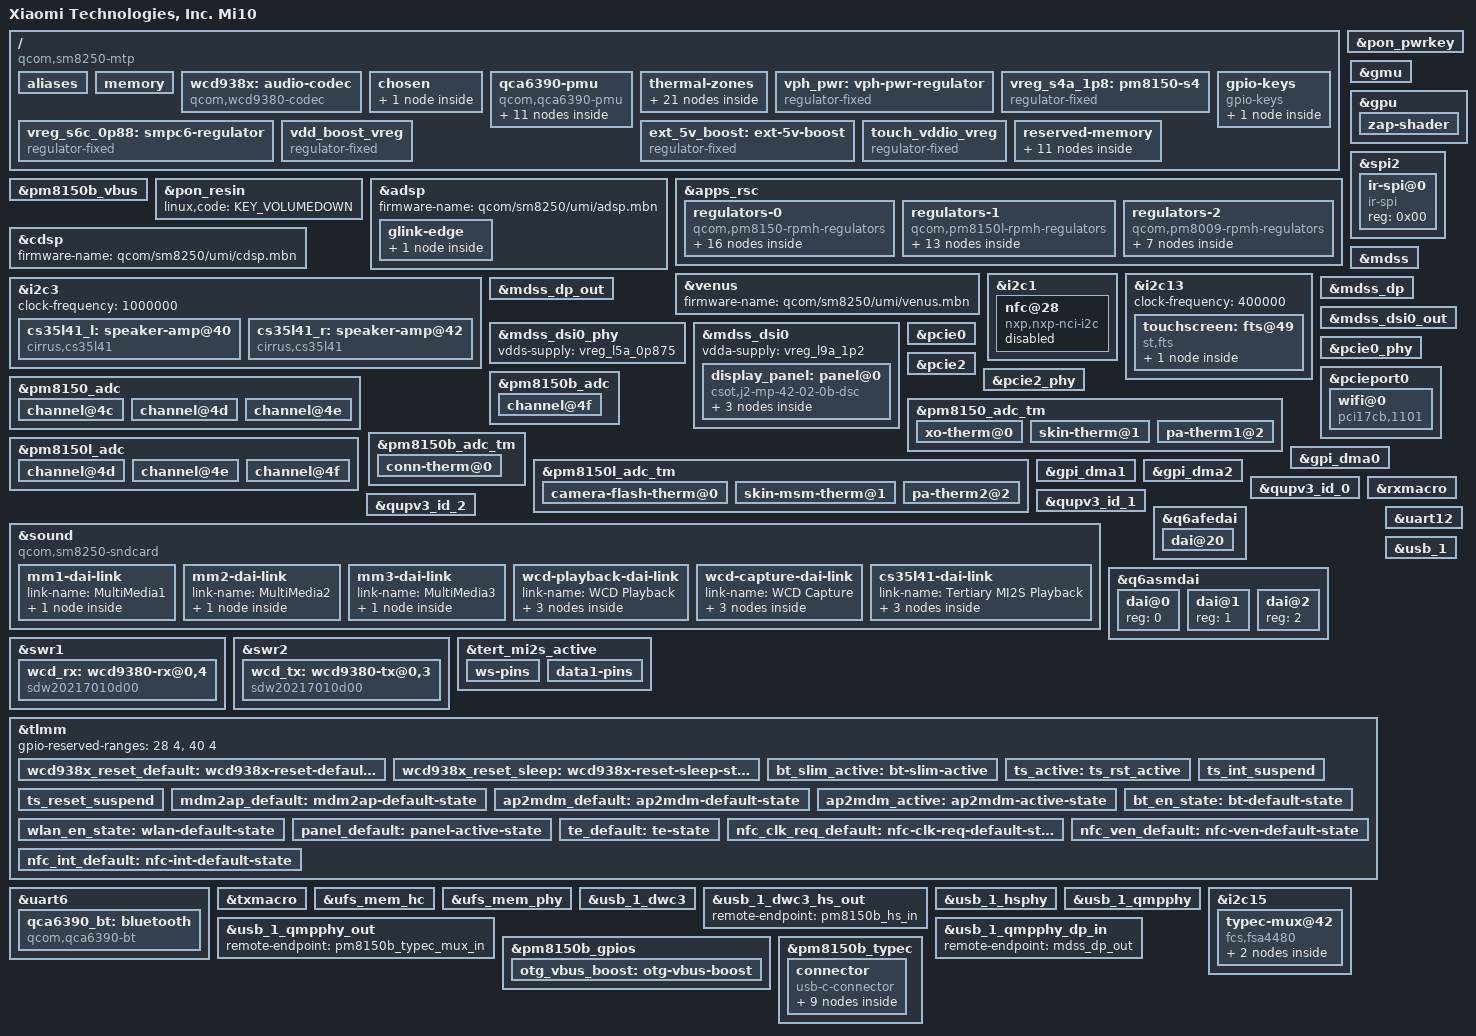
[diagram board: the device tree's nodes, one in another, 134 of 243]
// SPDX-License-Identifier: BSD-3-Clause
/*
 * Copyright (c) 2020, The Linux Foundation. All rights reserved.
 */

/dts-v1/;

#include <dt-bindings/regulator/qcom,rpmh-regulator.h>
#include <dt-bindings/sound/qcom,q6afe.h>
#include <dt-bindings/sound/qcom,q6asm.h>
#include <dt-bindings/gpio/gpio.h>
#include <dt-bindings/usb/pd.h>
#include "sm8250.dtsi"
#include "pm8150.dtsi"
#include "pm8150b.dtsi"
#include "pm8150l.dtsi"
#include "pm8009.dtsi"

/delete-node/ &adsp_mem;
/delete-node/ &cdsp_secure_heap;
/delete-node/ &slpi_mem;
/delete-node/ &spss_mem;
/delete-node/ &xbl_aop_mem;

/ {
	model = "Xiaomi Technologies, Inc. Mi10";
	compatible = "qcom,sm8250-mtp", "qcom,sm8250";
	chassis-type = "handset";
	qcom,msm-id = <0x164 0x20001>;
	qcom,board-id = <0x2b 0x00>;

	aliases {
		serial0 = &uart12;
		serial1 = &uart6;
	};
	
	memory {
		ddr_device_type = <0x08>;
		device_type = "memory";
		#address-cells = <2>;
		#size-cells = <2>;
		reg = 	<0x0 0x80000000 0x0 0x3b800000>,
				<0x1 0x80000000 0x1 0x0>,
				<0x0 0xc0000000 0x0 0xc0000000>;
	};

	wcd938x: audio-codec {
		compatible = "qcom,wcd9380-codec";
		status = "okay";
		reset-gpios = <&tlmm 32 GPIO_ACTIVE_LOW>;

		vdd-buck-supply = <&vreg_s4a_1p8>;
		vdd-rxtx-supply = <&vreg_s4a_1p8>;
		vdd-io-supply = <&vreg_s4a_1p8>;
		vdd-mic-bias-supply = <&vreg_bob>;

		qcom,micbias1-microvolt = <1800000>;
		qcom,micbias2-microvolt = <1800000>;
		qcom,micbias3-microvolt = <1800000>;
		qcom,micbias4-microvolt = <1800000>;
		qcom,mbhc-buttons-vthreshold-microvolt = <75000 150000 237000 500000 500000 500000 500000 500000>;
		qcom,mbhc-headset-vthreshold-microvolt = <1700000>;
		qcom,mbhc-headphone-vthreshold-microvolt = <50000>;
		qcom,rx-device = <&wcd_rx>;
		qcom,tx-device = <&wcd_tx>;

		#sound-dai-cells = <1>;
	};

	// battery: battery {
	// 	compatible = "simple-battery";
	// 	voltage-min-design-microvolt = <3400000>;
	// 	voltage-max-design-microvolt = <4400000>;
	// 	charge-full-design-microamp-hours = <4680000>;
	// 	energy-full-design-microwatt-hours = <18400000>;
	// };

	chosen {
		#address-cells = <2>;
		#size-cells = <2>;
		ranges;
		// stdout-path = "serial0:115200n8";
		// stdout-path = "display0";
		bootargs = "panic=30 loglevel=7 console=ttyS0,115200 console=tty1 rootfs_part=sda36 root=/dev/sda36 rw rootwait systemd.journald.forward_to_console=true systemd.log_level=debug systemd.log_target=kmsg log_buf_len=10M printk.devkmsg=on";
		//  pd_ignore_unused clk_ignore_unused 
		display0: framebuffer@9c000000 {
			compatible = "simple-framebuffer";
			reg = <0x0 0x9c000000 0x0 0x2300000>;
			width = <1080>;
			height = <2340>;
			stride = <(1080 * 4)>;
			format = "a8r8g8b8";
			status = "disabled";
			/*
			 * That's a lot of clocks, but it's necessary due
			 * to unused clk cleanup & no panel driver yet..
			 */
			// clocks = <&dispcc DISP_CC_MDSS_AHB_CLK>,
			// 	 <&gcc GCC_DISP_HF_AXI_CLK>,
			// 	 <&gcc GCC_DISP_SF_AXI_CLK>,
			// 	 <&dispcc DISP_CC_MDSS_VSYNC_CLK>,
			// 	 <&dispcc DISP_CC_MDSS_MDP_CLK>,
			// 	 <&dispcc DISP_CC_MDSS_BYTE0_CLK>,
			// 	 <&dispcc DISP_CC_MDSS_BYTE0_INTF_CLK>,
			// 	 <&dispcc DISP_CC_MDSS_PCLK0_CLK>,
			// 	 <&dispcc DISP_CC_MDSS_ESC0_CLK>;
			// power-domains = <&dispcc MDSS_GDSC>;
		};
	};

	qca6390-pmu {
		compatible = "qcom,qca6390-pmu";

		pinctrl-names = "default";
		pinctrl-0 = <&bt_en_state>, <&wlan_en_state>;

		vddaon-supply = <&vreg_s6a_0p95>;
		vddpmu-supply = <&vreg_s2f_0p95>;
		vddrfa0p95-supply = <&vreg_s2f_0p95>;
		vddrfa1p3-supply = <&vreg_s8c_1p3>;
		vddrfa1p9-supply = <&vreg_s5a_1p9>;
		vddpcie1p3-supply = <&vreg_s8c_1p3>;
		vddpcie1p9-supply = <&vreg_s5a_1p9>;
		vddio-supply = <&vreg_s4a_1p8>;

		wlan-enable-gpios = <&tlmm 20 GPIO_ACTIVE_HIGH>;
		bt-enable-gpios = <&tlmm 21 GPIO_ACTIVE_HIGH>;

		regulators {
			vreg_pmu_rfa_cmn: ldo0 {
				regulator-name = "vreg_pmu_rfa_cmn";
			};

			vreg_pmu_aon_0p59: ldo1 {
				regulator-name = "vreg_pmu_aon_0p59";
			};

			vreg_pmu_wlcx_0p8: ldo2 {
				regulator-name = "vreg_pmu_wlcx_0p8";
			};

			vreg_pmu_wlmx_0p85: ldo3 {
				regulator-name = "vreg_pmu_wlmx_0p85";
			};

			vreg_pmu_btcmx_0p85: ldo4 {
				regulator-name = "vreg_pmu_btcmx_0p85";
			};

			vreg_pmu_rfa_0p8: ldo5 {
				regulator-name = "vreg_pmu_rfa_0p8";
			};

			vreg_pmu_rfa_1p2: ldo6 {
				regulator-name = "vreg_pmu_rfa_1p2";
			};

			vreg_pmu_rfa_1p7: ldo7 {
				regulator-name = "vreg_pmu_rfa_1p7";
			};

			vreg_pmu_pcie_0p9: ldo8 {
				regulator-name = "vreg_pmu_pcie_0p9";
			};

			vreg_pmu_pcie_1p8: ldo9 {
				regulator-name = "vreg_pmu_pcie_1p8";
			};
		};
	};

	thermal-zones {
		camera-thermal {
			polling-delay-passive = <0>;
			polling-delay = <0>;
			thermal-sensors = <&pm8150l_adc_tm 0>;

			trips {
				active-config0 {
					temperature = <125000>;
					hysteresis = <1000>;
					type = "passive";
				};
			};
		};

		conn-thermal {
			polling-delay-passive = <0>;
			polling-delay = <0>;
			thermal-sensors = <&pm8150b_adc_tm 0>;

			trips {
				active-config0 {
					temperature = <125000>;
					hysteresis = <1000>;
					type = "passive";
				};
			};
		};

		mmw-pa1-thermal {
			polling-delay-passive = <0>;
			polling-delay = <0>;
			thermal-sensors = <&pm8150_adc_tm 2>;

			trips {
				active-config0 {
					temperature = <125000>;
					hysteresis = <1000>;
					type = "passive";
				};
			};
		};

		mmw-pa2-thermal {
			polling-delay-passive = <0>;
			polling-delay = <0>;
			thermal-sensors = <&pm8150l_adc_tm 2>;

			trips {
				active-config0 {
					temperature = <125000>;
					hysteresis = <1000>;
					type = "passive";
				};
			};
		};

		skin-msm-thermal {
			polling-delay-passive = <0>;
			polling-delay = <0>;
			thermal-sensors = <&pm8150l_adc_tm 1>;

			trips {
				active-config0 {
					temperature = <125000>;
					hysteresis = <1000>;
					type = "passive";
				};
			};
		};

		skin-thermal {
			polling-delay-passive = <0>;
			polling-delay = <0>;
			thermal-sensors = <&pm8150_adc_tm 1>;

			trips {
				active-config0 {
					temperature = <125000>;
					hysteresis = <1000>;
					type = "passive";
				};
			};
		};

		xo-thermal {
			polling-delay-passive = <0>;
			polling-delay = <0>;
			thermal-sensors = <&pm8150_adc_tm 0>;

			trips {
				active-config0 {
					temperature = <125000>;
					hysteresis = <1000>;
					type = "passive";
				};
			};
		};
	};

	// slimbam: dma-controller@3a84000 {
	// 	compatible = "qcom,bam-v1.7.4", "qcom,bam-v1.7.0";
	// 	reg = <0x0 0x3a84000 0x0 0x2c000>;
	// 	interrupts = <GIC_SPI 164 IRQ_TYPE_LEVEL_HIGH>;
	// 	#dma-cells = <1>;
	// 	qcom,ee = <1>;
	// 	qcom,num-ees = <2>;
	// 	num-channels = <31>;
	// 	qcom,controlled-remotely;
	// 	iommus = <&apps_smmu 0x1826 0x00>;
	// };

	// slim_msm: slim-ngd@3ac0000  {
	// 	compatible = "qcom,slim-ngd-v1.5.0";
	// 	reg = <0 0x3ac0000 0 0x2c000>;
	// 	interrupts = <GIC_SPI 163 IRQ_TYPE_LEVEL_HIGH>;
	// 	dmas = <&slimbam 3>, <&slimbam 4>;
	// 	dma-names = "rx", "tx";
	// 	#address-cells = <1>;
	// 	#size-cells = <0>;
	// 	iommus = <&apps_smmu 0x1830 0x01>,
	// 			<&apps_smmu 0x182f 0x00>;
	// 	status = "disabled";
	// };

	vph_pwr: vph-pwr-regulator {
		compatible = "regulator-fixed";
		regulator-name = "vph_pwr";
		regulator-min-microvolt = <3700000>;
		regulator-max-microvolt = <3700000>;
	};

	vreg_s4a_1p8: pm8150-s4 {
		compatible = "regulator-fixed";
		regulator-name = "vreg_s4a_1p8";

		regulator-min-microvolt = <1800000>;
		regulator-max-microvolt = <1800000>;

		regulator-always-on;
		regulator-boot-on;

		vin-supply = <&vph_pwr>;
	};

	vreg_s6c_0p88: smpc6-regulator {
		compatible = "regulator-fixed";
		regulator-name = "vreg_s6c_0p88";

		regulator-min-microvolt = <880000>;
		regulator-max-microvolt = <880000>;
		regulator-always-on;
		vin-supply = <&vph_pwr>;
	};

	gpio-keys {
		compatible = "gpio-keys";
		key-vol-up {
			label = "Volume Up";
			linux,code = <KEY_VOLUMEUP>;
			gpios = <&pm8150_gpios 6 GPIO_ACTIVE_LOW>;
		};
	};

	vdd_boost_vreg: vdd_boost_vreg {
		compatible = "regulator-fixed";
		regulator-name = "vdd_boost_vreg";
		regulator-min-microvolt = <5000000>;
		regulator-max-microvolt = <5000000>;
		startup-delay-us = <4000>;
		enable-active-high;
		regulator-always-on;
		gpio = <&pm8150b_gpios 5 0>;
	 };

	ext_5v_boost: ext-5v-boost {
		status = "okay";
		compatible = "regulator-fixed";
		gpio = <&pm8150b_gpios 12 GPIO_ACTIVE_HIGH>;
		pinctrl-names = "default";
		pinctrl-0 = <&otg_vbus_boost>;
		regulator-min-microvolt = <5000000>;
		regulator-max-microvolt = <5000000>;
		regulator-enable-ramp-delay = <1600>;
		regulator-name = "ext_5v_boost";
		enable-active-high;
	};

	touch_vddio_vreg: touch_vddio_vreg {
		status = "okay";
		compatible = "regulator-fixed";
		regulator-name = "disp_vddio_vreg";
		regulator-min-microvolt = <1800000>;
		regulator-max-microvolt = <1800000>;
		enable-active-high;
		gpio = <&tlmm 69 0>;
	};

	reserved-memory {
		xbl_aop_mem: memory@80600000 {
			reg = <0x0 0x80600000 0x0 0x260000>;
			no-map;
		};

		xbl_uefi_log: memory@80880000 {
			reg = <0x0 0x80880000 0x0 0x14000>;
			no-map;
		};

		slpi_mem: memory@88c00000 {
			reg = <0x0 0x88c00000 0x0 0x2f00000>;
			no-map;
		};

		adsp_mem: memory@8bb00000 {
			reg = <0x0 0x8bb00000 0x0 0x2500000>;
			no-map;
		};

		spss_mem: memory@8e000000 {
			reg = <0x0 0x8e000000 0x0 0x100000>;
			no-map;
		};

		cdsp_secure_heap: memory@8e100000 {
			reg = <0x0 0x8e100000 0x0 0x4600000>;
			no-map;
		};
		
		dfps_data_region: memory@9e300000 {
			reg = <0x0 0x9e300000 0x0 0x100000>;
			no-map;
		};

		disp_rdump_region: memory@b0400000 {
			reg = <0x0 0xb0400000 0x0 0x1000000>;
			no-map;
		};

		adsp_dma_mem: memory@9E400000 {
			reg = <0x0 0x9E400000 0x0 0xc00000>;
			no-map;
		};

		linux,cma {
			compatible = "shared-dma-pool";
			size = <0x0 0x8000000>;
			reusable;
			linux,cma-default;
		};

		// cont_splash_region@9c000000 {
		// 	reg = <0x0 0x9c000000 0x0 0x2300000>;
		// 	label = "cont_splash_region";
		// 	no-map;
		// };

		ramoops@b0000000 {
			compatible = "ramoops";
			reg = <0x0 0xb0000000 0x0 0x400000>;
			record-size = <0>;
			console-size = <0x200000>;
		};
	};
};

&pm8150b_vbus {
	regulator-min-microamp = <500000>;
	regulator-max-microamp = <3000000>;
	status = "okay";
};

&pon_pwrkey {
	status = "okay";
};

&pon_resin {
	status = "okay";
	linux,code = <KEY_VOLUMEDOWN>;
};

&adsp {
	status = "okay";
	firmware-name = "qcom/sm8250/umi/adsp.mbn";
	glink-edge {
		fastrpc {
			memory-region = <&adsp_dma_mem>;
		};
	};
};

// &slim_msm {
// 	status = "okay";
// };

&apps_rsc {
	regulators-0 {
		compatible = "qcom,pm8150-rpmh-regulators";
		qcom,pmic-id = "a";

		vdd-s1-supply = <&vph_pwr>;
		vdd-s2-supply = <&vph_pwr>;
		vdd-s3-supply = <&vph_pwr>;
		vdd-s4-supply = <&vph_pwr>;
		vdd-s5-supply = <&vph_pwr>;
		vdd-s6-supply = <&vph_pwr>;
		vdd-s7-supply = <&vph_pwr>;
		vdd-s8-supply = <&vph_pwr>;
		vdd-s9-supply = <&vph_pwr>;
		vdd-s10-supply = <&vph_pwr>;
		vdd-l1-l8-l11-supply = <&vreg_s6c_0p88>;
		vdd-l2-l10-supply = <&vreg_bob>;
		vdd-l3-l4-l5-l18-supply = <&vreg_s6a_0p95>;
		vdd-l6-l9-supply = <&vreg_s8c_1p3>;
		vdd-l7-l12-l14-l15-supply = <&vreg_s5a_1p9>;
		vdd-l13-l16-l17-supply = <&vreg_bob>;

		vreg_s5a_1p9: smps5 {
			regulator-name = "vreg_s5a_1p9";
			regulator-min-microvolt = <1904000>;
			regulator-max-microvolt = <2000000>;
			regulator-initial-mode = <RPMH_REGULATOR_MODE_HPM>;
		};

		vreg_s6a_0p95: smps6 {
			regulator-name = "vreg_s6a_0p95";
			regulator-min-microvolt = <920000>;
			regulator-max-microvolt = <1128000>;
			regulator-initial-mode = <RPMH_REGULATOR_MODE_HPM>;
		};

		vreg_l2a_3p1: ldo2 {
			regulator-name = "vreg_l2a_3p1";
			regulator-min-microvolt = <3072000>;
			regulator-max-microvolt = <3072000>;
			regulator-initial-mode = <RPMH_REGULATOR_MODE_HPM>;
		};

		vreg_l3a_0p9: ldo3 {
			regulator-name = "vreg_l3a_0p9";
			regulator-min-microvolt = <928000>;
			regulator-max-microvolt = <932000>;
			regulator-initial-mode = <RPMH_REGULATOR_MODE_HPM>;
		};

		vreg_l5a_0p875: ldo5 {
			regulator-name = "vreg_l5a_0p875";
			regulator-min-microvolt = <880000>;
			regulator-max-microvolt = <880000>;
			regulator-initial-mode = <RPMH_REGULATOR_MODE_HPM>;
		};

		vreg_l6a_1p2: ldo6 {
			regulator-name = "vreg_l6a_1p2";
			regulator-min-microvolt = <1200000>;
			regulator-max-microvolt = <1200000>;
			regulator-initial-mode = <RPMH_REGULATOR_MODE_HPM>;
		};

		vreg_l7a_1p7: ldo7 {
			regulator-name = "vreg_l7a_1p7";
			regulator-min-microvolt = <1704000>;
			regulator-max-microvolt = <1800000>;
			regulator-initial-mode = <RPMH_REGULATOR_MODE_HPM>;
		};

		vreg_l9a_1p2: ldo9 {
			regulator-name = "vreg_l9a_1p2";
			regulator-min-microvolt = <1200000>;
			regulator-max-microvolt = <1200000>;
			regulator-initial-mode = <RPMH_REGULATOR_MODE_HPM>;
		};

		vreg_l10a_1p8: ldo10 {
			regulator-name = "vreg_l10a_1p8";
			regulator-min-microvolt = <1800000>;
			regulator-max-microvolt = <1800000>;
			regulator-initial-mode = <RPMH_REGULATOR_MODE_HPM>;
		};

		vreg_l12a_1p8: ldo12 {
			regulator-name = "vreg_l12a_1p8";
			regulator-min-microvolt = <1800000>;
			regulator-max-microvolt = <1800000>;
			regulator-initial-mode = <RPMH_REGULATOR_MODE_HPM>;
		};

		vreg_l13a_ts_3p0: ldo13 {
			regulator-name = "vreg_l13a_ts_3p0";
			regulator-min-microvolt = <3008000>;
			regulator-max-microvolt = <3008000>;
			regulator-initial-mode = <RPMH_REGULATOR_MODE_HPM>;
		};

		vreg_l14a_1p8: ldo14 {
			regulator-name = "vreg_l14a_1p8";
			regulator-min-microvolt = <1800000>;
			regulator-max-microvolt = <1880000>;
			regulator-initial-mode = <RPMH_REGULATOR_MODE_HPM>;
		};

		vreg_l15a_11ad_io_1p8: ldo15 {
			regulator-name = "vreg_l15a_11ad_io_1p8";
			regulator-min-microvolt = <1800000>;
			regulator-max-microvolt = <1800000>;
			regulator-initial-mode = <RPMH_REGULATOR_MODE_HPM>;
		};

		vreg_l16a_3p3: ldo16 {
			regulator-name = "vreg_l16a_3p3";
			regulator-min-microvolt = <3024000>;
			regulator-max-microvolt = <3304000>;
			regulator-initial-mode = <RPMH_REGULATOR_MODE_HPM>;
		};

		vreg_l17a_3p0: ldo17 {
			regulator-name = "vreg_l17a_3p0";
			regulator-min-microvolt = <2856000>;
			regulator-max-microvolt = <3008000>;
			regulator-initial-mode = <RPMH_REGULATOR_MODE_HPM>;
		};

		vreg_l18a_0p9: ldo18 {
			regulator-name = "vreg_l18a_0p9";
			regulator-min-microvolt = <912000>;
			regulator-max-microvolt = <912000>;
			regulator-initial-mode = <RPMH_REGULATOR_MODE_HPM>;
		};
	};

	regulators-1 {
		compatible = "qcom,pm8150l-rpmh-regulators";
		qcom,pmic-id = "c";

		vdd-s1-supply = <&vph_pwr>;
		vdd-s2-supply = <&vph_pwr>;
		vdd-s3-supply = <&vph_pwr>;
		vdd-s4-supply = <&vph_pwr>;
		vdd-s5-supply = <&vph_pwr>;
		vdd-s6-supply = <&vph_pwr>;
		vdd-s7-supply = <&vph_pwr>;
		vdd-s8-supply = <&vph_pwr>;
		vdd-l1-l8-supply = <&vreg_s4a_1p8>;
		vdd-l2-l3-supply = <&vreg_s8c_1p3>;
		vdd-l4-l5-l6-supply = <&vreg_bob>;
		vdd-l7-l11-supply = <&vreg_bob>;
		vdd-l9-l10-supply = <&vreg_bob>;
		vdd-bob-supply = <&vph_pwr>;

		vreg_bob: bob {
			regulator-name = "vreg_bob";
			regulator-min-microvolt = <3008000>;
			regulator-max-microvolt = <4000000>;
			regulator-initial-mode = <RPMH_REGULATOR_MODE_AUTO>;
		};

		vreg_s8c_1p3: smps8 {
			regulator-name = "vreg_s8c_1p3";
			regulator-min-microvolt = <1352000>;
			regulator-max-microvolt = <1352000>;
			regulator-initial-mode = <RPMH_REGULATOR_MODE_HPM>;
		};

		vreg_l1c_1p8: ldo1 {
			regulator-name = "vreg_l1c_1p8";
			regulator-min-microvolt = <1800000>;
			regulator-max-microvolt = <1800000>;
			regulator-initial-mode = <RPMH_REGULATOR_MODE_HPM>;
			// regulator-always-on;
			// regulator-boot-on;
		};

		vreg_l2c_1p2: ldo2 {
			regulator-name = "vreg_l2c_1p2";
			regulator-min-microvolt = <1200000>;
			regulator-max-microvolt = <1200000>;
			regulator-initial-mode = <RPMH_REGULATOR_MODE_HPM>;
		};

		vreg_l3c_0p92: ldo3 {
			regulator-name = "vreg_l3c_0p92";
			regulator-min-microvolt = <920000>;
			regulator-max-microvolt = <920000>;
			regulator-initial-mode = <RPMH_REGULATOR_MODE_HPM>;
		};

		vreg_l4c_1p7: ldo4 {
			regulator-name = "vreg_l4c_1p7";
			regulator-min-microvolt = <1704000>;
			regulator-max-microvolt = <2928000>;
			regulator-initial-mode = <RPMH_REGULATOR_MODE_HPM>;
		};

		vreg_l5c_1p8: ldo5 {
			regulator-name = "vreg_l5c_1p8";
			regulator-min-microvolt = <1800000>;
			regulator-max-microvolt = <2928000>;
			regulator-initial-mode = <RPMH_REGULATOR_MODE_HPM>;
		};

		vreg_l6c_2p9: ldo6 {
			regulator-name = "vreg_l6c_2p9";
			regulator-min-microvolt = <1800000>;
			regulator-max-microvolt = <2960000>;
			regulator-initial-mode = <RPMH_REGULATOR_MODE_HPM>;
		};

		vreg_l7c_cam_vcm0_2p85: ldo7 {
			regulator-name = "vreg_l7c_cam_vcm0_2p85";
			regulator-min-microvolt = <2856000>;
			regulator-max-microvolt = <3104000>;
			regulator-initial-mode = <RPMH_REGULATOR_MODE_HPM>;
		};

		vreg_l8c_1p8: ldo8 {
			regulator-name = "vreg_l8c_1p8";
			regulator-min-microvolt = <1800000>;
			regulator-max-microvolt = <1800000>;
			regulator-initial-mode = <RPMH_REGULATOR_MODE_HPM>;
		};

		vreg_l9c_2p9: ldo9 {
			regulator-name = "vreg_l9c_2p9";
			regulator-min-microvolt = <2704000>;
			regulator-max-microvolt = <2960000>;
			regulator-initial-mode = <RPMH_REGULATOR_MODE_HPM>;
		};

		vreg_l10c_3p0: ldo10 {
			regulator-name = "vreg_l10c_3p0";
			regulator-min-microvolt = <3000000>;
			regulator-max-microvolt = <3000000>;
			regulator-initial-mode = <RPMH_REGULATOR_MODE_HPM>;
		};

		vreg_l11c_3p3: ldo11 {
			regulator-name = "vreg_l11c_3p3";
			regulator-min-microvolt = <3000000>;
			regulator-max-microvolt = <3312000>;
			regulator-initial-mode = <RPMH_REGULATOR_MODE_HPM>;
		};
	};

	regulators-2 {
		compatible = "qcom,pm8009-rpmh-regulators";
		qcom,pmic-id = "f";

		vdd-s1-supply = <&vph_pwr>;
		vdd-s2-supply = <&vreg_bob>;
		vdd-l2-supply = <&vreg_s8c_1p3>;
		vdd-l5-l6-supply = <&vreg_bob>;
		vdd-l7-supply = <&vreg_s4a_1p8>;

		vreg_s2f_0p95: smps2 {
			regulator-name = "vreg_s2f_0p95";
			regulator-min-microvolt = <900000>;
			regulator-max-microvolt = <952000>;
			regulator-initial-mode = <RPMH_REGULATOR_MODE_AUTO>;
		};

		vreg_l1f_cam_dvdd1_1p1: ldo1 {
			regulator-name = "vreg_l1f_cam_dvdd1_1p1";
			regulator-min-microvolt = <1104000>;
			regulator-max-microvolt = <1104000>;
			regulator-initial-mode = <RPMH_REGULATOR_MODE_HPM>;
		};

		vreg_l2f_cam_dvdd0_1p2: ldo2 {
			regulator-name = "vreg_l2f_cam_dvdd0_1p2";
			regulator-min-microvolt = <1200000>;
			regulator-max-microvolt = <1200000>;
			regulator-initial-mode = <RPMH_REGULATOR_MODE_HPM>;
		};

		vreg_l3f_cam_dvdd2_1p05: ldo3 {
			regulator-name = "vreg_l3f_cam_dvdd2_1p05";
			regulator-min-microvolt = <1056000>;
			regulator-max-microvolt = <1056000>;
			regulator-initial-mode = <RPMH_REGULATOR_MODE_HPM>;
		};

		vreg_l5f_cam_avdd0_2p85: ldo5 {
			regulator-name = "vreg_l5f_cam_avdd0_2p85";
			regulator-min-microvolt = <2800000>;
			regulator-max-microvolt = <2800000>;
			regulator-initial-mode = <RPMH_REGULATOR_MODE_HPM>;
		};

		vreg_l6f_cam_avdd1_2p85: ldo6 {
			regulator-name = "vreg_l6f_cam_avdd1_2p85";
			regulator-min-microvolt = <2856000>;
			regulator-max-microvolt = <2856000>;
			regulator-initial-mode = <RPMH_REGULATOR_MODE_HPM>;
		};

		vreg_l7f_1p8: ldo7 {
			regulator-name = "vreg_l7f_1p8";
			regulator-min-microvolt = <1800000>;
			regulator-max-microvolt = <1800000>;
			regulator-initial-mode = <RPMH_REGULATOR_MODE_HPM>;
		};
	};
};

&cdsp {
	status = "okay";
	firmware-name = "qcom/sm8250/umi/cdsp.mbn";
};

&venus {
	status = "okay";
	firmware-name = "qcom/sm8250/umi/venus.mbn";
};

&gmu {
	status = "okay";
};

&gpu {
	status = "okay";

	zap-shader {
		memory-region = <&gpu_mem>;
		firmware-name = "qcom/sm8250/umi/a650_zap.mbn";
	};
};

&i2c1 {
	status = "okay";

	nfc@28 {
		compatible = "nxp,nxp-nci-i2c";
		status = "disabled";
		reg = <0x28>;
		interrupt-parent = <&tlmm>;
		interrupts = <111 IRQ_TYPE_EDGE_RISING>;

		pinctrl-names = "default";
		pinctrl-0 = <&nfc_int_default>,
					<&nfc_ven_default>,
					<&nfc_clk_req_default>;

		enable-gpios = <&tlmm 83 GPIO_ACTIVE_HIGH>;
		firmware-gpios = <&tlmm 110 GPIO_ACTIVE_HIGH>;
	};
};

&spi2 {
	status = "okay";
	spi-max-frequency = <19200000>;
	status = "okay";
	pinctrl-names = "default";
	pinctrl-0 = <&qup_spi2_data_clk>, <&qup_spi2_cs_gpio>;
	cs-gpios = <&tlmm 118 GPIO_ACTIVE_LOW>;

	ir-spi@0 {
		compatible = "ir-spi";
		reg = <0x00>;
		status = "ok";
	};
};

&i2c3 {
	status = "okay";
	clock-frequency = <1000000>;

	cs35l41_l: speaker-amp@40 {
		compatible = "cirrus,cs35l41";
		status = "okay";
		reg = <0x40>;
		interrupt-parent = <&tlmm>;
		interrupts = <113 IRQ_TYPE_LEVEL_LOW>;
		reset-gpios = <&tlmm 114 GPIO_ACTIVE_HIGH>;
		cirrus,boost-peak-milliamp = <4000>;
		cirrus,boost-ind-nanohenry = <1000>;
		cirrus,boost-cap-microfarad = <15>;
		cirrus,asp-sdout-hiz = <1>;
		cirrus,gpio2-src-select = <4>;
		cirrus,gpio2-output-enable;
		sound-name-prefix = "L";
		#sound-dai-cells = <1>;
	};

	cs35l41_r: speaker-amp@42 {
		compatible = "cirrus,cs35l41";
		status = "okay";
		reg = <0x42>;
		interrupt-parent = <&tlmm>;
		interrupts = <112 IRQ_TYPE_LEVEL_LOW>;
		reset-gpios = <&tlmm 114 GPIO_ACTIVE_HIGH>;
		cirrus,boost-peak-milliamp = <4000>;
		cirrus,boost-ind-nanohenry = <1000>;
		cirrus,boost-cap-microfarad = <15>;
		cirrus,asp-sdout-hiz = <3>;
		cirrus,gpio2-src-select = <4>;
		cirrus,gpio2-output-enable;
		sound-name-prefix = "R";
		#sound-dai-cells = <1>;
	};
};

&i2c13 {
	clock-frequency = <400000>;
	status = "okay";

	/* st,fts @ 49 */
	touchscreen: fts@49 {
		status = "okay";
		compatible = "st,fts";
		reg = <0x49>;
		interrupt-parent = <&tlmm>;
		interrupts = <39 0x2008>;
		pinctrl-names = "pmx_ts_active", "pmx_ts_suspend";
		pinctrl-0 = <&ts_active>;
		pinctrl-1 = <&ts_int_suspend &ts_reset_suspend>;
		vdd-supply = <&touch_vddio_vreg>;
		avdd-supply = <&vreg_l1c_1p8>;
		fts,pwr-reg-name = "avdd";
		fts,bus-reg-name = "vdd";
		fts,irq-gpio = <&tlmm 39 0x2008>;
		fts,irq-gpio-name = "fts_irq";
		fts,reset-gpio-enable;
		fts,reset-gpio = <&tlmm 38 0x00>;
		fts,reset-gpio-name = "fts_rst";
		fts,irq-flags = <0x2008>; /* IRQF_ONESHOT | IRQF_TRIGGER_LOW */
		fts,x-max = <1080>;
		fts,y-max = <2340>;
		fts,default-fw-name = "st_fts_j2_2.ftb";
		fts,config-array-size = <1>;
		fts,cfg_0 {
			fts,tp-vendor = <0x48>;
			fts,fw-name = "st_fts_j2_2.ftb";
			fts,limit-name = "stm_fts_production_limits_2.csv";
		};
	};
};

&mdss {
	status = "okay";
};

&mdss_dp {
	status = "okay";
};

&mdss_dp_out {
	data-lanes = <0 1>;
	remote-endpoint = <&usb_1_qmpphy_dp_in>;
};

&mdss_dsi0_out {
	remote-endpoint = <&panel_in_0>;
	data-lanes = <0 1 2 3>;
};

&mdss_dsi0_phy {
	vdds-supply = <&vreg_l5a_0p875>;
	status = "okay";
};

&mdss_dsi0 {
	vdda-supply = <&vreg_l9a_1p2>;
	status = "okay";

	display_panel: panel@0 {
		reg = <0>;
		compatible = "csot,j2-mp-42-02-0b-dsc";
		vddio-supply = <&vreg_l14a_1p8>;
		reset-gpios = <&tlmm 12 GPIO_ACTIVE_LOW>;
		disprate-gpios = <&tlmm 50 GPIO_ACTIVE_HIGH>;
		
		pinctrl-names = "default";
		pinctrl-0 = <&panel_default>, <&te_default>;

		status = "okay";

		ports {
			#address-cells = <1>;
			#size-cells = <0>;

			port@0 {
				reg = <0>;

				panel_in_0: endpoint {
					remote-endpoint = <&mdss_dsi0_out>;
				};
			};
		};
	};
};

&pcie0 {
	status = "okay";
};

&pcie0_phy {
	vdda-phy-supply = <&vreg_l5a_0p875>;
	vdda-pll-supply = <&vreg_l9a_1p2>;
	status = "okay";
};

&pcieport0 {
	wifi@0 {
		compatible = "pci17cb,1101";
		reg = <0x10000 0x0 0x0 0x0 0x0>;

		vddrfacmn-supply = <&vreg_pmu_rfa_cmn>;
		vddaon-supply = <&vreg_pmu_aon_0p59>;
		vddwlcx-supply = <&vreg_pmu_wlcx_0p8>;
		vddwlmx-supply = <&vreg_pmu_wlmx_0p85>;
		vddrfa0p8-supply = <&vreg_pmu_rfa_0p8>;
		vddrfa1p2-supply = <&vreg_pmu_rfa_1p2>;
		vddrfa1p7-supply = <&vreg_pmu_rfa_1p7>;
		vddpcie0p9-supply = <&vreg_pmu_pcie_0p9>;
		vddpcie1p8-supply = <&vreg_pmu_pcie_1p8>;
	};
};

&pcie2 {
	status = "okay";
	pinctrl-0 = <&pcie2_default_state>, <&mdm2ap_default>, <&ap2mdm_default>, <&ap2mdm_active>, <&nfc_int_default>,
					<&nfc_ven_default>,
					<&nfc_clk_req_default>;
};

&pcie2_phy {
	vdda-phy-supply = <&vreg_l5a_0p875>;
	vdda-pll-supply = <&vreg_l9a_1p2>;
	status = "okay";
};

&pm8150_adc {
	channel@4c {
		reg = <ADC5_XO_THERM_100K_PU>;
		qcom,ratiometric;
		qcom,hw-settle-time = <200>;
		label = "xo_therm";
	};

	channel@4d {
		reg = <ADC5_AMUX_THM1_100K_PU>;
		qcom,ratiometric;
		qcom,hw-settle-time = <200>;
		label = "skin_therm";
	};

	channel@4e {
		reg = <ADC5_AMUX_THM2_100K_PU>;
		qcom,ratiometric;
		qcom,hw-settle-time = <200>;
		label = "pa_therm1";
	};
};

&pm8150_adc_tm {
	status = "okay";

	xo-therm@0 {
		reg = <0>;
		io-channels = <&pm8150_adc ADC5_XO_THERM_100K_PU>;
		qcom,ratiometric;
		qcom,hw-settle-time-us = <200>;
	};

	skin-therm@1 {
		reg = <1>;
		io-channels = <&pm8150_adc ADC5_AMUX_THM1_100K_PU>;
		qcom,ratiometric;
		qcom,hw-settle-time-us = <200>;
	};

	pa-therm1@2 {
		reg = <2>;
		io-channels = <&pm8150_adc ADC5_AMUX_THM2_100K_PU>;
		qcom,ratiometric;
		qcom,hw-settle-time-us = <200>;
	};
};

&pm8150b_adc {
	channel@4f {
		reg = <ADC5_AMUX_THM3_100K_PU>;
		qcom,ratiometric;
		qcom,hw-settle-time = <200>;
		label = "conn_therm";
	};
};

&pm8150b_adc_tm {
	status = "okay";

	conn-therm@0 {
		reg = <0>;
		io-channels = <&pm8150b_adc ADC5_AMUX_THM3_100K_PU>;
		qcom,ratiometric;
		qcom,hw-settle-time-us = <200>;
	};
};

&pm8150l_adc_tm {
	status = "okay";

	camera-flash-therm@0 {
		reg = <0>;
		io-channels = <&pm8150l_adc ADC5_AMUX_THM1_100K_PU>;
		qcom,ratiometric;
		qcom,hw-settle-time-us = <200>;
	};

	skin-msm-therm@1 {
		reg = <1>;
		io-channels = <&pm8150l_adc ADC5_AMUX_THM2_100K_PU>;
		qcom,ratiometric;
		qcom,hw-settle-time-us = <200>;
	};

	pa-therm2@2 {
		reg = <2>;
		io-channels = <&pm8150l_adc ADC5_AMUX_THM3_100K_PU>;
		qcom,ratiometric;
		qcom,hw-settle-time-us = <200>;
	};
};

&pm8150l_adc {
	channel@4d {
		reg = <ADC5_AMUX_THM1_100K_PU>;
		qcom,ratiometric;
		qcom,hw-settle-time = <200>;
		label = "camera_flash_therm";
	};

	channel@4e {
		reg = <ADC5_AMUX_THM2_100K_PU>;
		qcom,ratiometric;
		qcom,hw-settle-time = <200>;
		label = "skin_msm_therm";
	};

	channel@4f {
		reg = <ADC5_AMUX_THM3_100K_PU>;
		qcom,ratiometric;
		qcom,hw-settle-time = <200>;
		label = "pa_therm2";
	};
};

&gpi_dma0 {
	status = "okay";
};

&gpi_dma1 {
	status = "okay";
};

&gpi_dma2 {
	status = "okay";
};

&qupv3_id_0 {
	status = "okay";
};

&qupv3_id_1 {
	status = "okay";
};

&qupv3_id_2 {
	status = "okay";
};

&rxmacro {
	status = "okay";
};

// &slpi {
// 	status = "okay";
// 	firmware-name = "qcom/sm8250/umi/slpi.mbn";
// };

&sound {
	status = "okay";
	compatible = "qcom,sm8250-sndcard";
	model = "XIAOMI-UMI-WCD9380-CS35L41-VA-DMIC";
	pinctrl-names = "default";
	pinctrl-0 = <&tert_mi2s_active>;

	audio-routing =
		"L ASPRX1", 		"MM_DL1",
		"L DSP RX1 Source", "L ASPRX1",
		"L DSP1", 			"L DSP RX1 Source",
		"L PCM Source", 	"L DSP1",
		"R ASPRX1", 		"MM_DL1",
		"R DSP RX1 Source", "R ASPRX1",
		"R DSP1", 			"R DSP RX1 Source",
		"R PCM Source", 	"R DSP1",
		"IN1_HPHL", "HPHL_OUT",
		"IN2_HPHR", "HPHR_OUT",
		"AMIC1", "MIC BIAS1",
		"AMIC2", "MIC BIAS2",
		"AMIC3", "MIC BIAS3",
		"AMIC5", "MIC BIAS4",
		"MM_DL1",  "MultiMedia1 Playback",
		"MM_DL2",  "MultiMedia2 Playback",
		"MultiMedia3 Capture", "MM_UL3";

	mm1-dai-link {
		link-name = "MultiMedia1";
		cpu {
			sound-dai = <&q6asmdai  MSM_FRONTEND_DAI_MULTIMEDIA1>;
		};
	};

	mm2-dai-link {
		link-name = "MultiMedia2";
		cpu {
			sound-dai = <&q6asmdai  MSM_FRONTEND_DAI_MULTIMEDIA2>;
		};
	};

	mm3-dai-link {
		link-name = "MultiMedia3";
		cpu {
			sound-dai = <&q6asmdai  MSM_FRONTEND_DAI_MULTIMEDIA3>;
		};
	};

	wcd-playback-dai-link {
		link-name = "WCD Playback";
		cpu {
			sound-dai = <&q6afedai RX_CODEC_DMA_RX_0>;
		};
		codec {
			sound-dai = <&wcd938x 0>, <&swr1 0>, <&rxmacro 0>;
		};
		platform {
			sound-dai = <&q6routing>;
		};
	};

	wcd-capture-dai-link {
		link-name = "WCD Capture";
		cpu {
			sound-dai = <&q6afedai TX_CODEC_DMA_TX_3>;
		};

		codec {
			sound-dai = <&wcd938x 1>, <&swr2 0>, <&txmacro 0>;
		};

		platform {
			sound-dai = <&q6routing>;
		};
	};

	cs35l41-dai-link {
		link-name = "Tertiary MI2S Playback";
		cpu {
			sound-dai = <&q6afedai TERTIARY_MI2S_RX>;
		};

		platform {
			sound-dai = <&q6routing>;
		};

		codec {
			sound-dai = <&cs35l41_l 0>, <&cs35l41_r 0>;
		};
	};

	// bt-slim-playback-dai-link {
	// 	link-name = "Bluetooth Slimbus Playback";
	// 	cpu {
	// 		sound-dai = <&q6afedai SLIMBUS_0_TX>;
	// 	};

	// 	platform {
	// 		sound-dai = <&qca6390_bt 0>;
	// 	};

	// 	// codec {
	// 	// 	sound-dai = <&qca6390_bt 0>;
	// 	// };
	// };

	// bt-slim-capture-dai-link {
	// 	link-name = "Bluetooth Slimbus Capture";
	// 	cpu {
	// 		sound-dai = <&q6afedai SLIMBUS_0_RX>;
	// 	};

	// 	platform {
	// 		sound-dai = <&q6routing>;
	// 	};
		
	// 	// codec {
	// 	// 	sound-dai = <&qca6390_bt 0>;
	// 	// };
	// };
};

&q6afedai {
	dai@20 {
		reg = <TERTIARY_MI2S_RX>;
		qcom,sd-lines = <1>;
	};
};

&q6asmdai {
	dai@0 {
		reg = <0>;
	};

	dai@1 {
		reg = <1>;
	};

	dai@2 {
		reg = <2>;
	};
};

&swr1 {
	status = "okay";
	wcd_rx: wcd9380-rx@0,4 {
		compatible = "sdw20217010d00";
		reg = <0 4>;
		qcom,rx-port-mapping = <1 2 3 4 5>;
	};
};

&swr2 {
	status = "okay";
	wcd_tx: wcd9380-tx@0,3 {
		compatible = "sdw20217010d00";
		reg = <0 3>;
		qcom,tx-port-mapping = <2 3 4 5>;
	};
};

&tert_mi2s_active {
	/delete-node/ data0-pins;

	ws-pins {
		/delete-property/ output-high;
	};

	data1-pins {
		pins = "gpio137";
		function = "mi2s2_data1";
		drive-strength = <8>;
		bias-disable;
		// output-high;
	};
};

&tlmm {
	gpio-reserved-ranges = <28 4>, <40 4>;

	wcd938x_reset_default: wcd938x-reset-default-state {
		pins = "gpio32";
		function = "gpio";
		drive-strength = <16>;
		output-high;
	};

	wcd938x_reset_sleep: wcd938x-reset-sleep-state {
		pins = "gpio32";
		function = "gpio";
		drive-strength = <16>;
		bias-disable;
		output-low;
	};
	
	bt_slim_active: bt-slim-active {
		pins = "gpio142", "gpio143";
		function = "lpass_slimbus";
		drive-strength = <8>;
		bias-disable;
	};

	ts_active: ts_rst_active {
		pins = "gpio38", "gpio39";
		function = "gpio";
		drive-strength = <8>;
		bias-pull-up;
	};

	ts_int_suspend: ts_int_suspend {
		pins = "gpio39";
		function = "gpio";
		drive-strength = <2>;
		bias-pull-down;
	};

	ts_reset_suspend: ts_reset_suspend {
		pins = "gpio38";
		function = "gpio";
		drive-strength = <2>;
		bias-pull-down;
	};

	mdm2ap_default: mdm2ap-default-state {
		pins = "gpio1", "gpio3";
		function = "gpio";
		drive-strength = <8>;
		bias-disable;
	};

	ap2mdm_default: ap2mdm-default-state {
		pins = "gpio57";
		function = "gpio";
		drive-strength = <16>;
		bias-disable;
		output-low;
	};

	ap2mdm_active: ap2mdm-active-state {
		pins = "gpio56";
		function = "gpio";
		drive-strength = <16>;
		bias-disable;
		output-high;
	};

	bt_en_state: bt-default-state {
		pins = "gpio21";
		function = "gpio";
		drive-strength = <16>;
		output-high;
		bias-pull-up;
	};

	wlan_en_state: wlan-default-state {
		pins = "gpio20";
		function = "gpio";
		drive-strength = <16>;
		output-low;
		bias-pull-up;
	};

	panel_default: panel-active-state {
		pins = "gpio12";
		function = "gpio";
		drive-strength = <8>;
		bias-disable;
	};

	te_default: te-state {
		pins = "gpio66";
		function = "mdp_vsync";
		drive-strength = <2>;
		bias-pull-down;
	};

	nfc_clk_req_default: nfc-clk-req-default-state {
		pins = "gpio7";
		function = "gpio";
		drive-strength = <2>;
		bias-pull-up;
	};

	nfc_ven_default: nfc-ven-default-state {
		pins = "gpio83", "gpio110";
		function = "gpio";
		drive-strength = <2>;
		bias-pull-up;
	};

	nfc_int_default: nfc-int-default-state {
		pins = "gpio111";
		function = "gpio";
		drive-strength = <2>;
		bias-pull-up;
		input-enable;
	};
};

&uart6 {
	status = "okay";

	qca6390_bt: bluetooth {
		compatible = "qcom,qca6390-bt";
		// When will it support btfm ?
		// #sound-dai-cells = <0>;
		vddrfacmn-supply = <&vreg_pmu_rfa_cmn>;
		vddaon-supply = <&vreg_pmu_aon_0p59>;
		vddbtcmx-supply = <&vreg_pmu_btcmx_0p85>;
		vddrfa0p8-supply = <&vreg_pmu_rfa_0p8>;
		vddrfa1p2-supply = <&vreg_pmu_rfa_1p2>;
		vddrfa1p7-supply = <&vreg_pmu_rfa_1p7>;		
	};
};

&txmacro {
	status = "okay";
};

&uart12 {
	status = "okay";
};

&ufs_mem_hc {
	status = "okay";
	vcc-supply = <&vreg_l17a_3p0>;
	vcc-max-microamp = <800000>;
	vccq-supply = <&vreg_l6a_1p2>;
	vccq-max-microamp = <800000>;
	vccq2-supply = <&vreg_s4a_1p8>;
	vccq2-max-microamp = <800000>;
};

&ufs_mem_phy {
	status = "okay";
	vdda-phy-supply = <&vreg_l5a_0p875>;
	vdda-pll-supply = <&vreg_l9a_1p2>;
};

&usb_1 {
	status = "okay";
};

&usb_1_dwc3 {
	dr_mode = "otg";
	// dr_mode = "peripheral";
	usb-role-switch;
};

&usb_1_dwc3_hs_out {
	remote-endpoint = <&pm8150b_hs_in>;
};

&usb_1_hsphy {
	status = "okay";
	vdda-pll-supply = <&vreg_l5a_0p875>;
	vdda18-supply = <&vreg_l12a_1p8>;
	vdda33-supply = <&vreg_l2a_3p1>;
};

&usb_1_qmpphy {
	status = "okay";
	vdda-phy-supply = <&vreg_l9a_1p2>;
	vdda-pll-supply = <&vreg_l18a_0p9>;
};

&i2c15 {
	status = "okay";

	typec-mux@42 {
		compatible = "fcs,fsa4480";
		reg = <0x42>;
		mode-switch;
		orientation-switch;
		port {
			fsa4480_sbu_mux: endpoint {
				remote-endpoint = <&pm8150b_typec_sbu_out>;
			};
		};
	};
};

&usb_1_qmpphy_out {
	remote-endpoint = <&pm8150b_typec_mux_in>;
};

&usb_1_qmpphy_dp_in {
	remote-endpoint = <&mdss_dp_out>;
};

&pm8150b_gpios {
	otg_vbus_boost: otg-vbus-boost {
		pins = "gpio12";
		function = "normal";
		power-source = <0x00>;
		output-low;
	};
};

&pm8150b_typec {
	status = "okay";

	vdd-pdphy-supply = <&vreg_l2a_3p1>;
	vdd-vbus-supply = <&ext_5v_boost>;

	connector {
		compatible = "usb-c-connector";
		label = "USB-C";

		power-role = "source";
		data-role = "dual";
		self-powered;
		accessory-mode-audio = <1>;

		source-pdos = <PDO_FIXED(5000, 3000,
					 PDO_FIXED_DUAL_ROLE |
					 PDO_FIXED_USB_COMM |
					 PDO_FIXED_DATA_SWAP)>;

		altmodes {
			displayport {
				svid = /bits/ 16 <0xff01>;
				vdo = <0x00001c46>;
			};
		};

		ports {
			#address-cells = <1>;
			#size-cells = <0>;

			port@0 {
				reg = <0>;
				pm8150b_hs_in: endpoint {
					remote-endpoint = <&usb_1_dwc3_hs_out>;
				};
			};

			port@1 {
				reg = <1>;
				pm8150b_typec_mux_in: endpoint {
					remote-endpoint = <&usb_1_qmpphy_out>;
				};
			};

			port@2 {
				reg = <2>;

				pm8150b_typec_sbu_out: endpoint {
					remote-endpoint = <&fsa4480_sbu_mux>;
				};
			};
		};
	};
};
